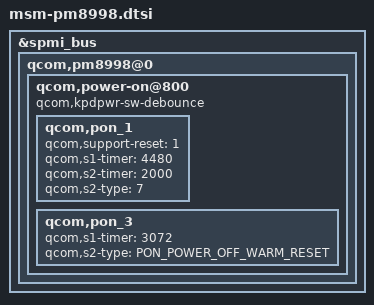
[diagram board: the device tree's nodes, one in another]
/* Copyright (c) 2016-2017, The Linux Foundation. All rights reserved.
 *
 * This program is free software; you can redistribute it and/or modify
 * it under the terms of the GNU General Public License version 2 and
 * only version 2 as published by the Free Software Foundation.
 *
 * This program is distributed in the hope that it will be useful,
 * but WITHOUT ANY WARRANTY; without even the implied warranty of
 * MERCHANTABILITY or FITNESS FOR A PARTICULAR PURPOSE.  See the
 * GNU General Public License for more details.
 */

&spmi_bus {
	qcom,pm8998@0 {
		qcom,power-on@800 {
			qcom,kpdpwr-sw-debounce;
			qcom,pon_1 {
				qcom,support-reset = <1>;
				qcom,s1-timer = <4480>;
				qcom,s2-timer = <2000>;
				qcom,s2-type = <7>;
			};

			qcom,pon_3 {
				qcom,s1-timer = <3072>;
				qcom,s2-type = <PON_POWER_OFF_WARM_RESET>;
			};
		};
	};
};
